# QSPI_1.0 register map
Vendor: Texas Instruments
Peripheral module from a debugger description file (folder mspm33c321x).
Registers are 32-bit, read-write, no defined reset value unless marked. A register's access mark holds for its fields unless they carry their own. Offsets are as the file gives them; lines under a group give offsets from that group; [hi:lo] are bit positions; {n}, {i} and the like mark numbered series; 'fields as' and 'values as' point back to an identical list; <NAME> marks a mode.

## QSPI
0x800 QSPI_GPRCM group
  0x00 QSPI_PWREN — Power enable
    [0] ENABLE — Enable the power
      0=DISABLE (Disable Power); 1=ENABLE (Enable Power)
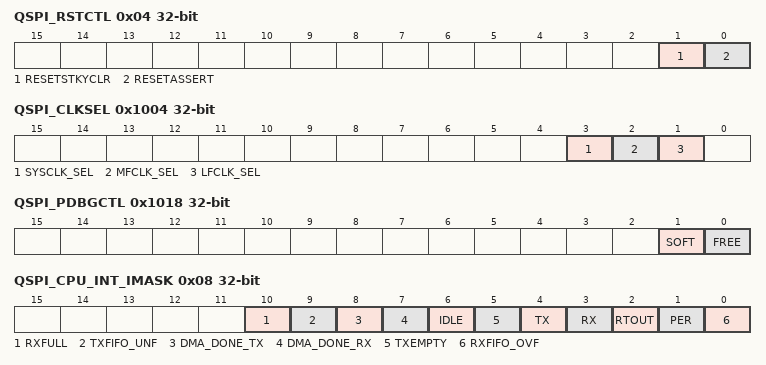
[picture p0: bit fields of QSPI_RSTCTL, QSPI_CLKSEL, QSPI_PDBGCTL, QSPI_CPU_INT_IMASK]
  0x04 QSPI_RSTCTL — Reset Control
    [1] RESETSTKYCLR — Clear the RESETSTKY bit in the STAT register
      0=NOP (Writing 0 has no effect); 1=CLR (Clear reset sticky bit)
    [0] RESETASSERT — Assert reset to the peripheral
      0=NOP (Writing 0 has no effect); 1=ASSERT (Assert reset)
  0x08 QSPI_CLKCFG — Peripheral Clock Configuration Register
    [8] BLOCKASYNC — Async Clock Request is blocked from starting SYSOSC or forcing bus clock to 32MHz
      0=DISABLE (Not block async clock request); 1=ENABLE (Block async clock request)
  0x14 QSPI_GPRCM_STAT ro — Status Register
    [16] RESETSTKY — This bit indicates, if the peripheral was reset, since this bit was cleared by RESETSTKYCLR in the RSTCTL register
      0=NORES (The peripheral has not been reset since this bit was last cleared by RESETSTKYCLR in the RSTCTL register); 1=RESET (The peripheral was reset since the last bit clear)
0x1000 QSPI_CLKDIV — Clock Divider
  [2:0] RATIO — Selects divide ratio of module clock
    0=DIV_BY_1 (Do not divide clock source); {v}=DIV_BY_{v+1} (Divide clock source by {v+1}) (v=1..7)
0x1004 QSPI_CLKSEL — Clock Select for Ultra Low Power peripherals
  [all] fields
    0=DISABLE (Does not select this clock as a source); 1=ENABLE (Select this clock as a source)
  [3] SYSCLK_SEL — Selects SYSCLK as clock source if enabled
  [2] MFCLK_SEL — Selects MFCLK as clock source if enabled
  [1] LFCLK_SEL — Selects LFCLK as clock source if enabled
0x1018 QSPI_PDBGCTL — Peripheral Debug Control
  [1] SOFT — Soft halt boundary control. This function is only available, if [FREE] is set to 'STOP'
    0=IMMEDIATE (The peripheral will halt immediately, even if the resultant state will result in corruption if the system is restarted); 1=DELAYED (The peripheral blocks the debug freeze until it has reached a boundary where it can resume without corruption)
  [0] FREE — Free run control
    0=STOP (The peripheral freezes functionality while the Core Halted input is asserted and resumes when it is deasserted.); 1=RUN (The peripheral ignores the state of the Core Halted input)
0x1020 QSPI_CPU_INT group
  0x00 QSPI_CPU_INT_IIDX ro — Interrupt Index Register
    [7:0] STAT — Interrupt index status
      0=NO_INTR (No interrupt pending); 1=RXFIFO_OFV_EVT (RX FIFO Overflow Event/interrupt pending); 2=PER_EVT (Transmit Parity Event/interrupt pending); 3=RTOUT_EVT (SPI receive time-out interrupt); 4=RX_EVT (Receive Event/interrupt pending); 5=TX_EVT (Transmit Event/interrupt pending); 6=TX_EMPTY (Transmit Buffer Empty Event/interrupt pending); 7=IDLE_EVT (End of Transmit Event/interrupt pending); 8=DMA_DONE_RX_EVT (DMA Done for Receive Event/interrupt pending); 9=DMA_DONE_TX_EVT (DMA Done for Transmit Event/interrupt pending); 10=TXFIFO_UNF_EVT (TX FIFO underflow interrupt); 11=RXFULL_EVT (RX FIFO Full Interrupt)
  0x08 QSPI_CPU_INT_IMASK — Interrupt mask
    [all] fields
      0=CLR (Clear Interrupt Mask); 1=SET (Set Interrupt Mask)
    [10] RXFULL — RX FIFO Full Interrupt Mask
    [9] TXFIFO_UNF — TX FIFO underflow interrupt mask
    [8] DMA_DONE_TX — DMA Done 1 event for TX event mask.
    [7] DMA_DONE_RX — DMA Done 1 event for RX event mask.
    [6] IDLE — SPI Idle event mask.
    [5] TXEMPTY — Transmit FIFO Empty event mask.
    [4] TX — Transmit FIFO event mask.
    [3] RX — Receive FIFO event.This interrupt is set if the selected Receive FIFO level has been reached
    [2] RTOUT — Enable SPI Receive Time-Out event mask.
    [1] PER — Parity error event mask.
    [0] RXFIFO_OVF — RXFIFO overflow event mask.
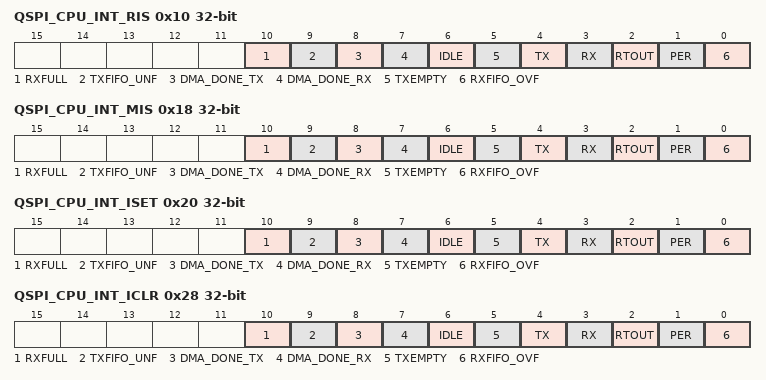
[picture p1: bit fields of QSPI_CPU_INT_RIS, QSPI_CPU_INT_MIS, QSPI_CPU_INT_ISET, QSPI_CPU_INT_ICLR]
  0x10 QSPI_CPU_INT_RIS — Raw interrupt status
    [all] fields
      0=CLR (Interrupt did not occur); 1=SET (Interrupt occurred)
    [10] RXFULL — RX FIFO Full Interrupt
    [9] TXFIFO_UNF — TX FIFO Underflow Interrupt
    [8] DMA_DONE_TX — DMA Done 1 event for TX. This interrupt is set if the TX DMA channel sends the DONE signal. This allows the handling of the DMA event inside the mapped peripheral.
    [7] DMA_DONE_RX — DMA Done 1 event for RX. This interrupt is set if the RX DMA channel sends the DONE signal. This allows the handling of the DMA event inside the mapped peripheral.
    [6] IDLE — SPI has done finished transfers and changed into IDLE mode. This bit is set when BUSY goes low.
    [5] TXEMPTY — Transmit FIFO Empty interrupt mask. This interrupt is set if all data in the Transmit FIFO have been move to the shift register.
    [4] TX — Transmit FIFO event..This interrupt is set if the selected Transmit FIFO level has been reached.
    [3] RX — Receive FIFO event.This interrupt is set if the selected Receive FIFO level has been reached
    [2] RTOUT — SPI Receive Time-Out event.
    [1] PER — Parity error event: this bit is set if a Parity error has been detected
    [0] RXFIFO_OVF — RXFIFO overflow event. This interrupt is set if an RX FIFO overflow has been detected.
  0x18 QSPI_CPU_INT_MIS — Masked interrupt status
    [10] RXFULL — RX FIFO Full Interrupt
      0=CLR (Interrupt did not occur); 1=SET (Interrupt occurred)
    [9] TXFIFO_UNF — TX FIFO underflow interrupt
      0=CLR (Interrupt did not occur); 1=SET (Interrupt occurred)
    [8] DMA_DONE_TX — Masked DMA Done 1 event for TX.
      0=CLR (Interrupt did not occur); 1=SET (Interrupt occurred)
    [7] DMA_DONE_RX — Masked DMA Done 1 event for RX.
      0=CLR (Interrupt did not occur); 1=SET (Interrupt occurred)
    [6] IDLE — Masked SPI IDLE mode event.
      0=CLR (Interrupt did not occur); 1=SET (Interrupt occurred)
    [5] TXEMPTY — Masked Transmit FIFO Empty event.
      0=CLR (Interrupt did not occur); 1=SET (Interrupt occurred)
    [4] TX — Masked Transmit FIFO event. This interrupt is set if the selected Transmit FIFO level has been reached.
      0=CLR (Interrupt did not occur); 1=SET (Interrupt occurred)
    [3] RX — Masked receive FIFO event.This interrupt is set if the selected Receive FIFO level has been reached
      0=CLR (Interrupt did not occur); 1=SET (Interrupt occurred)
    [2] RTOUT — Masked SPI Receive Time-Out Interrupt.
      0=CLR (Clear Interrupt Mask); 1=SET (Set Interrupt Mask)
    [1] PER — Masked Parity error event: this bit if a Parity error has been detected
      0=CLR (Interrupt did not occur); 1=SET (Interrupt occurred)
    [0] RXFIFO_OVF — Masked RXFIFO overflow event. This interrupt is set if an RX FIFO overflow has been detected.
      0=CLR (Interrupt did not occur); 1=SET (Interrupt occurred)
  0x20 QSPI_CPU_INT_ISET — Interrupt set
    [10] RXFULL — Set RX FIFO Full Event
      0=NO_EFFECT (Writing has no effect); 1=SET (Set Interrupt)
    [9] TXFIFO_UNF — Set TX FIFO Underflow Event
      0=NO_EFFECT (Writing has no effect); 1=SET (Set interrupt)
    [8] DMA_DONE_TX — Set DMA Done 1 event for TX.
      0=NO_EFFECT (Writing 0 has no effect); 1=SET (Set Interrupt)
    [7] DMA_DONE_RX — Set DMA Done 1 event for RX.
      0=NO_EFFECT (Writing 0 has no effect); 1=SET (Set Interrupt)
    [6] IDLE — Set SPI IDLE mode event.
      0=NO_EFFECT (Writing 0 has no effect); 1=SET (Set Interrupt)
    [5] TXEMPTY — Set Transmit FIFO Empty event.
      0=NO_EFFECT (Writing 0 has no effect); 1=SET (Set Interrupt)
    [4] TX — Set Transmit FIFO event.
      0=NO_EFFECT (Writing 0 has no effect); 1=SET (Set Interrupt)
    [3] RX — Set Receive FIFO event.
      0=NO_EFFECT (Writing 0 has no effect); 1=SET (Set Interrupt)
    [2] RTOUT — Set SPI Receive Time-Out Event.
      0=NO_EFFECT (Writing 0 has no effect); 1=SET (Set Interrupt Mask)
    [1] PER — Set Parity error event.
      0=NO_EFFECT (Writing 0 has no effect); 1=SET (Set Interrupt)
    [0] RXFIFO_OVF — Set RXFIFO overflow event.
      0=NO_EFFECT (Writing 0 has no effect); 1=SET (Set Interrupt)
  0x28 QSPI_CPU_INT_ICLR — Interrupt clear
    [10] RXFULL — Clear RX FIFO underflow event
      0=NO_EFFECT (Writing has no effect); 1=CLR (Clear interrupt)
    [9] TXFIFO_UNF — Clear TXFIFO underflow event
      0=NO_EFFECT (Writing has no effect); 1=CLR (Clear interrupt)
    [8] DMA_DONE_TX — Clear DMA Done 1 event for TX.
      0=NO_EFFECT (Writing 0 has no effect); 1=CLR (Clear Interrupt)
    [7] DMA_DONE_RX — Clear DMA Done 1 event for RX.
      values as DMA_DONE_TX
    [6] IDLE — Clear SPI IDLE mode event.
      values as DMA_DONE_TX
    [5] TXEMPTY — Clear Transmit FIFO Empty event.
      values as DMA_DONE_TX
    [4] TX — Clear Transmit FIFO event.
      values as DMA_DONE_TX
    [3] RX — Clear Receive FIFO event.
      values as DMA_DONE_TX
    [2] RTOUT — Clear SPI Receive Time-Out Event.
      0=NO_EFFECT (Writing 0 has no effect); 1=CLR (Set Interrupt Mask)
    [1] PER — Clear Parity error event.
      values as DMA_DONE_TX
    [0] RXFIFO_OVF — Clear RXFIFO overflow event.
      values as DMA_DONE_TX
0x1050 QSPI_DMA_TRIG_RX group
  0x00 QSPI_DMA_TRIG_RX_IIDX ro — Interrupt Index Register
    [7:0] STAT — Interrupt index status
      0=NO_INTR (No interrupt pending); 3=RTOUT_EVT (SPI receive time-out interrupt); 4=RX_EVT (Receive Event/interrupt pending)
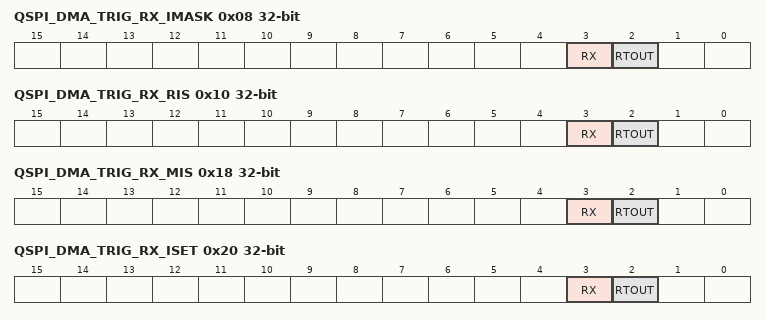
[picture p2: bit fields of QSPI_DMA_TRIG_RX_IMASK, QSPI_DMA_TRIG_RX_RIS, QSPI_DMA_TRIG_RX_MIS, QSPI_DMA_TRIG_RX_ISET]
  0x08 QSPI_DMA_TRIG_RX_IMASK — Interrupt mask
    [3] RX — Receive FIFO event mask.
      0=CLR (Clear Interrupt Mask); 1=SET (Set Interrupt Mask)
    [2] RTOUT — SPI Receive Time-Out event mask.
      0=CLR (Clear Interrupt Mask); 1=SET (Set Interrupt Mask)
  0x10 QSPI_DMA_TRIG_RX_RIS — Raw interrupt status
    [3] RX — Receive FIFO event.This interrupt is set if the selected Receive FIFO level has been reached
      0=CLR (Interrupt did not occur); 1=SET (Interrupt occurred)
    [2] RTOUT — SPI Receive Time-Out Event.
      0=CLR (Clear Interrupt Mask); 1=SET (Set Interrupt Mask)
  0x18 QSPI_DMA_TRIG_RX_MIS — Masked interrupt status
    [3] RX — Receive FIFO event mask.
      0=CLR (Interrupt did not occur); 1=SET (Interrupt occurred)
    [2] RTOUT — SPI Receive Time-Out event mask.
      0=CLR (Clear Interrupt Mask); 1=SET (Set Interrupt Mask)
  0x20 QSPI_DMA_TRIG_RX_ISET — Interrupt set
    [3] RX — Set Receive FIFO event.
      0=NO_EFFECT (Writing 0 has no effect); 1=SET (Set Interrupt)
    [2] RTOUT — Set SPI Receive Time-Out event.
      values as QSPI_CPU_INT.QSPI_CPU_INT_ISET.RTOUT
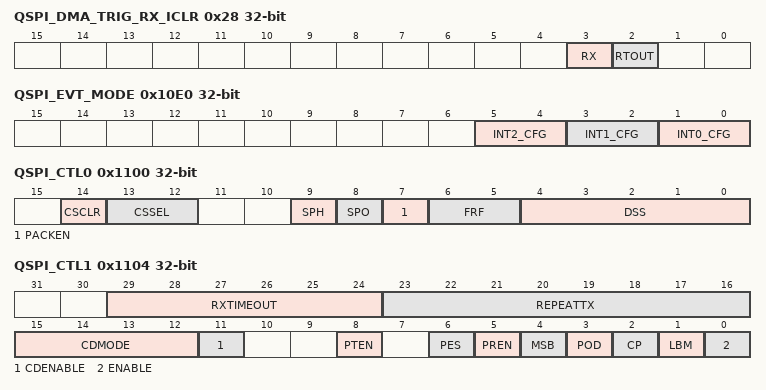
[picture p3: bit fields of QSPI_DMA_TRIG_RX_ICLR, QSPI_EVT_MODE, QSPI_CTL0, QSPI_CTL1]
  0x28 QSPI_DMA_TRIG_RX_ICLR — Interrupt clear
    [3] RX — Clear Receive FIFO event.
      values as QSPI_CPU_INT.QSPI_CPU_INT_ICLR.DMA_DONE_TX
    [2] RTOUT — Clear SPI Receive Time-Out event.
      values as QSPI_CPU_INT.QSPI_CPU_INT_ICLR.RTOUT
0x1080 QSPI_DMA_TRIG_TX group
  0x00 QSPI_DMA_TRIG_TX_IIDX ro — Interrupt Index Register
    [7:0] STAT — Interrupt index status
      0=NO_INTR (No interrupt pending); 5=TX_EVT (Transmit Event/interrupt pending)
  0x08 QSPI_DMA_TRIG_TX_IMASK — Interrupt mask
    [4] TX — Transmit FIFO event mask.
      0=CLR (Clear Interrupt Mask); 1=SET (Set Interrupt Mask)
  0x10 QSPI_DMA_TRIG_TX_RIS — Raw interrupt status
    [4] TX — Transmit FIFO event: A read returns the current mask for transmit FIFO interrupt. On a write of 1, the mask for transmit FIFO interrupt is set which means the interrupt state will be reflected in MIS.TXMIS. A write of 0 clears the mask which means MIS.TXMIS will not reflect the interrupt.
      0=CLR (Interrupt did not occur); 1=SET (Interrupt occurred)
  0x18 QSPI_DMA_TRIG_TX_MIS — Masked interrupt status
    [4] TX — Masked Transmit FIFO event
      0=CLR (Interrupt did not occur); 1=SET (Interrupt occurred)
  0x20 QSPI_DMA_TRIG_TX_ISET — Interrupt set
    [4] TX — Set Transmit FIFO event.
      0=NO_EFFECT (Writing 0 has no effect); 1=SET (Set Interrupt)
  0x28 QSPI_DMA_TRIG_TX_ICLR — Interrupt clear
    [4] TX — Clear Transmit FIFO event.
      values as QSPI_CPU_INT.QSPI_CPU_INT_ICLR.DMA_DONE_TX
0x10E0 QSPI_EVT_MODE ro — Event Mode
  [all] fields
    0=DISABLE (The interrupt or event line is disabled.); 1=SOFTWARE (The interrupt or event line is in software mode. Software must clear the RIS.); 2=HARDWARE (The interrupt or event line is in hardware mode. The hardware (another module) clears automatically the associated RIS flag.)
  [5:4] INT2_CFG — Event line mode select for event corresponding to [IPSTANDARD.INT_EVENT2]
  [3:2] INT1_CFG — Event line mode select for event corresponding to [IPSTANDARD.INT_EVENT1]
  [1:0] INT0_CFG — Event line mode select for event corresponding to [IPSTANDARD.INT_EVENT0]
0x10E4 QSPI_INTCTL — Interrupt control register
  [0] INTEVAL — Writing a 1 to this field re-evaluates the interrupt sources.
    0=DISABLE (The interrupt or event line is disabled.); 1=EVAL (The interrupt or event line is in software mode. Software must clear the RIS.)
0x1100 QSPI_CTL0 — SPI control register 0
  [14] CSCLR — Clear shift register counter on CS inactive This bit is relevant only in the peripheral, CTL1.CP=0.
    0=DISABLE (Disable automatic clear of shift register when CS goes to disable.); 1=ENABLE (Enable automatic clear of shift register when CS goes to disable.)
  [13:12] CSSEL — Select the CS line to control on data transfer This bit is applicable for both controller/target mode
    {v}=CS line select: {v} (v=0..3)
  [9] SPH — CLKOUT phase (Motorola SPI frame format only) This bit selects the clock edge that captures data and enables it to change state. It has the most impact on the first bit transmitted by either permitting or not permitting a clock transition before the first data capture edge.
    0=FIRST (Data is captured on the first clock edge transition.); 1=SECOND (Data is captured on the second clock edge transition.)
  [8] SPO — CLKOUT polarity (Motorola SPI frame format only)
    0=LOW (SPI produces a steady state LOW value on the CLKOUT); 1=HIGH (SPI produces a steady state HIGH value on the CLKOUT)
  [7] PACKEN — Packing Enable. When 1, packing feature is enabled inside the IP When 0, packing feature is disabled inside the IP
    0=DISABLED (Packing feature disabled); 1=ENABLED (Packing feature enabled)
  [6:5] FRF — Frame format Select
    0=MOTOROLA_3WIRE (Motorola SPI frame format (3 wire mode)); 1=MOTOROLA_4WIRE (Motorola SPI frame format (4 wire mode)); 2=TI_SYNC (TI synchronous serial frame format); 3=MIRCOWIRE (National Microwire frame format)
  [4:0] DSS — Data Size Select. Values 0 - 2 are reserved and shall not be used. 3h = 4_BIT : 4-bit data SPI allows only values up to 16 Bit
    {v}=Data Size Select bits: {v+1} (v=3..15)
0x1104 QSPI_CTL1 — SPI control register 1
  [29:24] RXTIMEOUT — Receive Timeout (only for Peripheral mode) Defines the number of Clock Cycles before after which the Receive Timeout flag RTOUT is set. The time is calculated using the control register for the clock selection and divider in the Controller mode configuration. A value of 0 disables this function.
    0=MINIMUM (Smallest value); 63=MAXIMUM (Highest possible value)
  [23:16] REPEATTX — Counter to repeat last transfer 0: repeat last transfer is disabled. x: repeat the last transfer with the given number. The transfer will be started with writing a data into the TX Buffer. Sending the data will be repeated with the given value, so the data will be transferred X+1 times in total. The behavior is identical as if the data would be written into the TX Buffer that many times as defined by the value here. It can be used to clean a transfer or to pull a certain amount of data by a peripheral.
    0=DISABLE (REPEATTX disable); 0=MINIMUM (Smallest value); 255=MAXIMUM (Highest possible value)
  [15:12] CDMODE — Command/Data Mode Value When CTL1.CDENABLE is 1, CS3 line is used as C/D signal to distinguish between Command (C/D low) and Data (C/D high) information. When a value is written into the CTL1.CDMODE bits, the C/D (CS3) line will go low for the given numbers of byte which are sent by the SPI, starting with the next value to be transmitted after which, C/D line will go high automatically 0: Manual mode with C/D signal as High 1-14: C/D is low while this number of bytes are being sent after which, this field sets to 0 and C/D goes high. Reading this field at any time returns the remaining number of command bytes. 15: Manual mode with C/D signal as Low.
    0=MINIMUM (Smallest value); 0=DATA (Manual mode: Data); 15=MAXIMUM (Highest possible value); 15=COMMAND (Manual mode: Command)
  [11] CDENABLE — Command/Data Mode enable
    0=DISABLE (CS3 is used for Chip Select); 1=ENABLE (CS3 is used as CD signal)
  [8] PTEN — Parity transmit enable If enabled, parity transmission will be done for both controller and peripheral modes.
    0=DISABLE (Parity transmission is disabled); 1=ENABLE (Parity transmission is enabled)
  [6] PES — Even Parity Select
    0=DISABLE (Odd Parity mode); 1=ENABLE (Even Parity mode)
  [5] PREN — Parity receive enable If enabled, parity reception check will be done for both controller and peripheral modes In case of a parity miss-match the parity error flag RIS.PER will be set.
    0=DISABLE (Disable Parity receive function); 1=ENABLE (Enable Parity receive function)
  [4] MSB — MSB first select. Controls the direction of the receive and transmit shift register.
    0=DISABLE (LSB first); 1=ENABLE (MSB first)
  [3] POD — Peripheral-mode: Data output disabled This bit is relevant only in Peripheral mode. In multiple-peripheral system topologies, SPI controller can broadcast a message to all peripherals, while only one peripheral drives the line. POD can be used by the SPI peripheral to disable driving data on the line.
    0=DISABLE (SPI can drive the MISO output in peripheral mode.); 1=ENABLE (SPI cannot drive the MISO output in peripheral mode.)
  [2] CP — Controller or peripheral mode select. This bit can be modified only when SPI is disabled, CTL1.ENABLE=0.
    0=DISABLE (Select Peripheral mode); 1=ENABLE (Select Controller Mode)
  [1] LBM — Loop back mode
    0=DISABLE (Disable loopback mode); 1=ENABLE (Enable loopback mode)
  [0] ENABLE — SPI enable
    0=DISABLE (Disable module function); 1=ENABLE (Enable module function)
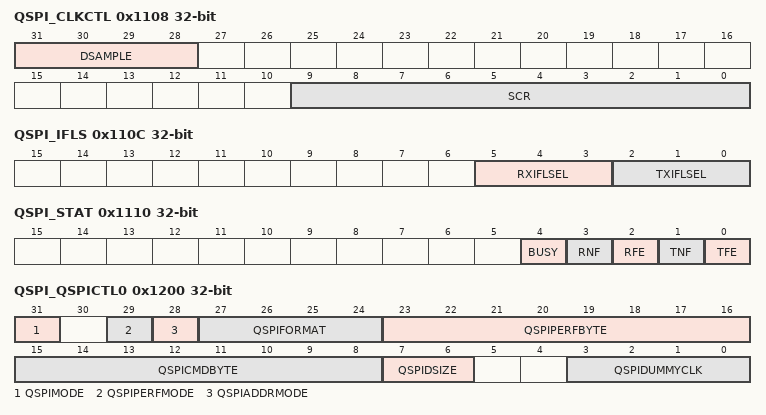
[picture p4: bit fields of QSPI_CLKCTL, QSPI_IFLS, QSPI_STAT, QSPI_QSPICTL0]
0x1108 QSPI_CLKCTL — Clock prescaler and divider register.
  [31:28] DSAMPLE — Delayed sampling value. In controller mode the data on the input pin will be delayed sampled by the defined clock cycles of internal functional clock hence relaxing the setup time of input data. This setting is useful in systems where the board delays and external peripheral delays are more than the input setup time of the controller. Please refer to the datasheet for values of controller input setup time and assess what DSAMPLE value meets the requirement of the system. Note: High values of DSAMPLE can cause HOLD time violations and must be factored in the calculations.
    0=MINIMUM (Smallest value); 15=MAXIMUM (Highest possible value)
  [9:0] SCR — Serial clock divider: This is used to generate the transmit and receive bit rate of the SPI. The SPI bit rate is (SPI's functional clock frequency)/((SCR+1)*2). SCR is a value from 0-1023.
    0=MINIMUM (Smallest value); 0x3FF=MAXIMUM (Highest possible value)
0x110C QSPI_IFLS — Interrupt FIFO Level Select Register
  [5:3] RXIFLSEL — SPI Receive Interrupt FIFO Level Select The trigger points for the receive interrupt are as follows:
    0=LVL_OFF (Reserved); 1=LVL_1_4 (RX FIFO >= 1/4 full); 2=LVL_1_2 (RX FIFO >= 1/2 full (default)); 3=LVL_3_4 (RX FIFO >= 3/4 full); 4=LVL_RES4 (Reserved); 5=LVL_FULL (RX FIFO is full); 6=LVL_RES6 (Reserved); 7=LEVEL_1 (Trigger when RX FIFO contains >= 1 frame)
  [2:0] TXIFLSEL — SPI Transmit Interrupt FIFO Level Select The trigger points for the transmit interrupt are as follows:
    0=LVL_OFF (Reserved); 1=LVL_3_4 (TX FIFO <= 3/4 empty); 2=LVL_1_2 (TX FIFO <= 1/2 empty (default)); 3=LVL_1_4 (TX FIFO <= 1/4 empty); 4=LVL_RES4 (Reserved); 5=LVL_EMPTY (TX FIFO is empty); 6=LVL_RES6 (Reserved); 7=LEVEL_1 (Trigger when TX FIFO has >= 1 frame free Should be used with DMA)
0x1110 QSPI_STAT — Status Register
  [4] BUSY
    0=IDLE (SPI is in idle mode.); 1=ACTIVE (SPI is currently transmitting and/or receiving data, or transmit FIFO is not empty.)
  [3] RNF — Receive FIFO not full
    0=FULL (Receive FIFO is full.); 1=NOT_FULL (Receive FIFO is not full.)
  [2] RFE — Receive FIFO empty.
    0=NOT_EMPTY (Receive FIFO is not empty.); 1=EMPTY (Receive FIFO is empty.)
  [1] TNF — Transmit FIFO not full
    0=FULL (Transmit FIFO is full.); 1=NOT_FULL (Transmit FIFO is not full.)
  [0] TFE — Transmit FIFO empty.
    0=NOT_EMPTY (Transmit FIFO is not empty.); 1=EMPTY (Transmit FIFO is empty.)
0x1130 QSPI_RXDATA ro — RXDATA Register
  [15:0] DATA — Received Data When PACKEN=1,two entries of the FIFO are returned as a 32-bit value. When PACKEN=0, 1 entry of FIFO is returned as 16-bit value. As data values are removed by the receive logic from the incoming data frame, they are placed into the entry in the receive FIFO, pointed to by the current FIFO write pointer. Received data less than 16 bits is automatically right justified in the receive buffer.
0x1140 QSPI_TXDATA — TXDATA Register
  [15:0] DATA — Transmit Data When read, last written value will be returned. If the last write to this field was a 32-bit write (with PACKEN=1), 32-bits will be returned and if the last write was a 16-bit write (PACKEN=0), those 16-bits will be returned. When written, one or two FIFO entries will be written depending on PACKEN value. Data values are removed from the transmit FIFO one value at a time by the transmit logic. It is loaded into the transmit serial shifter, then serially shifted out onto the TXD output pin at the programmed bit rate. When a data size of less than 16 bits is selected, the user must right-justify data written to the transmit FIFO. The transmit logic ignores the unused bits.
0x1200 QSPI_QSPICTL0 access per field — QSPI Control-0 register
  [31] QSPIMODE ro — This bits selects which port is used for QSPI memory access
    0=PERIPH_PORT (Selects peripheral port for external flash access); 1=DIRECT_PORT (Selects direct port for external flash access)
  [29] QSPIPERFMODE rw — This bit enables or disables the performance mode byte insertion
    0=DISABLE (Performance mode is disabled); 1=ENABLE (Performance mode is enabled)
  [28] QSPIADDRMODE rw — The bit field sets the number of address byte to be used for communication with QSPI flash during a data read
    0=_3BYTE_ADDR (Use 3-byte address); 1=_4BYTE_ADDR (Use 4-byte address)
  [27:24] QSPIFORMAT rw — The bits provides the bus format to be used
    0=LEGACY_SPI_FULLDUPLEX (Legacy SPI format full-duplex); 1=SPI_HALFDUPLEX (SPI format half-duplex when not sending a data read frame); 2=QPI_HALF_DUPLEX (QPI format half-duplex when not sending a data read frame); 8=SSS_MODE (SSS format when sending a data read frame); 9=SSD_MODE (SSD format when sending a data read frame); 10=SDD_MODE (SDD format when sending a data read frame); 11=SSQ_MODE (SSQ format when sending a data read frame); 12=SQQ_MODE (SQQ format when sending a data read frame); 13=QQQ_MODE (QQQ format when sending a data read frame)
  [23:16] QSPIPERFBYTE rw — The register bits provide the performance byte to be used during a flash read
    0=MINIMUM (Samllest value); 255=MAXIMUM (Largest value)
  [15:8] QSPICMDBYTE rw — The register bits provide the instruction opcode to be used during a flash read
    0=MINIMUM (Smallest value); 255=MAXIMUM (Largest value)
  [7:6] QSPIDSIZE rw — The register bits provide the packing and unpacking option from the FIFO to the flash interface
    0=_8BITDSIZE (Sets 8-bit data write and read from FIFO); 2=_16BITDSIZE (Sets 16-bit data write and read from FIFO); 3=_32BITDSIZE (Sets 32-bit data write and read from FIFO)
  [3:0] QSPIDUMMYCLK rw — The bits provides the number of dummy clocks to insert during a flash read operation
    0=MINIMUM (Smallest value); 15=MAXIMUM (Largest possible value)
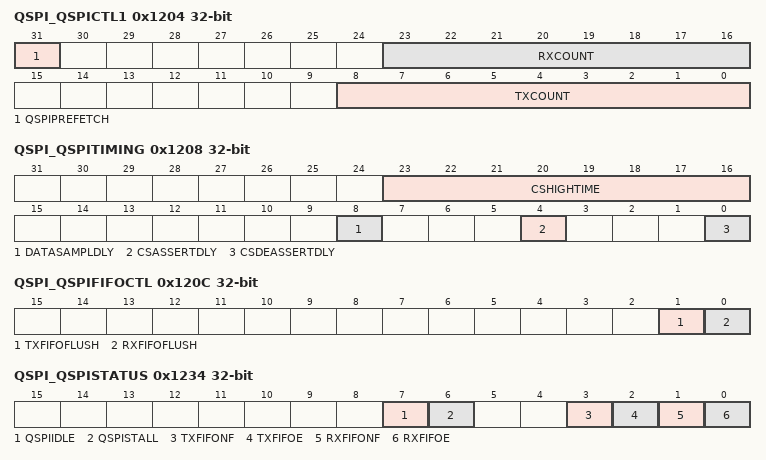
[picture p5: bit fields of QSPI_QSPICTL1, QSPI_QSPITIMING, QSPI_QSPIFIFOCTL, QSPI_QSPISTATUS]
0x1204 QSPI_QSPICTL1 — QSPI Control-1 Register
  [31] QSPIPREFETCH — Controls prefetch of data when the read transaction is started
    0=DISABLE (Prefetch is disabled); 1=ENABLE (Prefetch is enabled)
  [23:16] RXCOUNT
    0=RXFIFOMON (Only RXFIFO full level is monitored.); 1=MINIMUM (Smalles possible value); 255=MAXIMUM (Highest possible value)
  [8:0] TXCOUNT
    0=MINIMUM (Smallest possible value); 255=MAXIMUM (Highest possible value)
0x1208 QSPI_QSPITIMING access per field — The register is controls the timing setting for chip select assertion and de-assertion with respect to the serial clock, sampling delay for the data and chip-select behavior in performance mode
  [23:16] CSHIGHTIME ro — When in performance mode, the parameter provides the number of bus clocks for which the CS shgall be high when an address change is detected
    0=MINIMUM (Smallest value); 255=MAXIMUM (Largest value)
  [8] DATASAMPLDLY rw — When in QSPI mode, controls the sampling of the received data
    0=NODELAY (Received data is sampled on the rising edge of SCLK); 1=_1CLKDELAY (Received data is delayed by 1 SCLK before being sampled)
  [4] CSASSERTDLY rw — When in QSPI mode the bit controls the number of serial clock edge after chip select is asserted to start the SCLK
    0=_0P5SCLKDELAY (SCLK is started 0.5 internal SCLK after CS is asserted); 1=_1P5SCLKDELAY (SCLK is started 1.5 internal SCLK after CS is asserted)
  [0] CSDEASSERTDLY rw — When in QSPI mode the bit controls the number of serial clock edge after last SCLK to deassert the chip select
    0=_0P5SCLKDELAY (Chip select is deasserted 0.5 internal SCLK after last edge of the external SCLK); 1=_1P5SCLKDELAY (Chip select is deasserted 1.5 internal SCLK after last edge of the external SCLK)
0x120C QSPI_QSPIFIFOCTL — The register controls the flush operation in the peripheral FIFO
  [1] TXFIFOFLUSH — The bit is used to reset the TXFIFO pointers to flush any data from the preceding transaction.
    0=NOEFFECT; 1=CLEAR (Resets the TXFIFO and any corresponding status bit. The field will be auto-cleared after TXFIFO is reset)
  [0] RXFIFOFLUSH — The bit is used to reset the RXFIFO pointers to flush any data from the preceding transaction.
    0=NOEFFECT; 1=CLEAR (Resets the RXFIFO and any corresponding status bit. The field will be auto-cleared after RXFIFO is reset)
0x1210 QSPI_QSPICSCTL — The register controls the toggling of chip select
  [31] CSHOLDCTL — Controls the chip select hold feature during an active transaction when QSPIFORMAT is not 0x0
    0=NOEFFECT; 1=DEASSERT (When written as 1, causes the chip select to be deasserted after the current bus transaction is completed)
0x1220 QSPI_QSPIDMACTL — The register is used to generate a soft trigger for the DMA
  [0] DMATRIG
    0=DMATRIG_NOEFFECT (Writing the bit as 0 has no effect); 1=DMATRIG_ENABLE (Writing this bit as 1 asserts a DMA request)
0x1234 QSPI_QSPISTATUS ro — The register contains the status bits for the QSPI controller and the FIFO
  [7] QSPIIDLE — Provides the state of the QSPI controller
    0=QSPIIDLE_ACT (The QSPI has an active transaction ongoing or stalled and the chip select is low); 1=QSPIIDLE_IDLE (The QSPI does not have an active transaction and the chip select is high)
  [6] QSPISTALL — The bit indicates the state of the QSPI controller during an active transaction
    0=QSPISTALL_ACTIVE (The QSPI is sending or receiving data bytes from the memory); 1=QSPISTALL_STALL (The QSPI is currently stalled on the TXFIFO empty to have data or RXFIFO empty to have space to receive data)
  [3] TXFIFONF — Transmit FIFO not full status
    0=TXFIFONF_F (Transmit FIFO is full); 1=TXFIFONF_NF (Transmit FIFO is not full)
  [2] TXFIFOE — Transmit FIFO empty status
    0=TXFIFOE_NE (Transmit FIFO is not empty); 1=TXFIFOE_E (Transmit FIFO is empty)
  [1] RXFIFONF — Receive FIFO not full status
    0=RXFIFONF_F (Receive FIFO is full); 1=RXFIFONF_NF (Receive FIFO is not full)
  [0] RXFIFOE — Receive FIFO status empty status
    0=RXFIFOE_NE (Receive FIFO is not empty); 1=RXFIFOE_E (Receive FIFO is empty)
